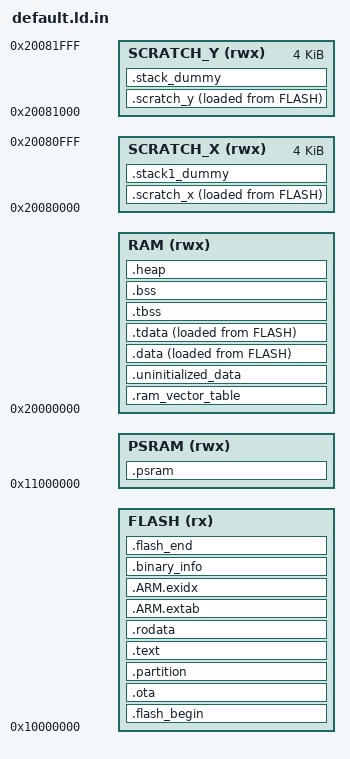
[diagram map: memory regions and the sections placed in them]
MEMORY
{
    FLASH(rx) : ORIGIN = 0x10000000, LENGTH = @FLASH_LENGTH@
    PSRAM(rwx) : ORIGIN = 0x11000000, LENGTH = @PSRAM_LENGTH@
    RAM(rwx) : ORIGIN = 0x20000000, LENGTH = @RAM_LENGTH@
    SCRATCH_X(rwx) : ORIGIN = 0x20080000, LENGTH = 4k
    SCRATCH_Y(rwx) : ORIGIN = 0x20081000, LENGTH = 4k
}

PROVIDE ( _EEPROM_start = @EEPROM_START@ );
PROVIDE ( _FS_start     = @FS_START@ );
PROVIDE ( _FS_end       = @FS_END@ );

ENTRY(_entry_point)

SECTIONS
{
    .flash_begin : {
        __flash_binary_start = .;
    } > FLASH

    .ota : {
        KEEP (*(.OTA))
        *ota.o
    } > FLASH

    .partition : {
        . = __flash_binary_start + 0x2ff0;
        LONG(@FS_START@)
        LONG(@FS_END@)
        LONG(@EEPROM_START@)
        LONG(@FLASH_LENGTH@)
    } > FLASH

    .text : {
        KEEP (*(.vectors))
        __logical_binary_start = .;
        KEEP (*(.binary_info_header))
        __binary_info_header_end = .;
        KEEP (*(.embedded_block))
        __embedded_block_end = .;
        KEEP (*(.reset))
        *(.init)
        *libgcc.a:cmse_nonsecure_call.o
        *(EXCLUDE_FILE(*libgcc.a: *libc.a:*lib_a-mem*.o *libm.a:) .text*)
        *(.fini)
        *crtbegin.o(.ctors)
        *crtbegin?.o(.ctors)
        *(EXCLUDE_FILE(*crtend?.o *crtend.o) .ctors)
        *(SORT(.ctors.*))
        *(.ctors)
        *crtbegin.o(.dtors)
        *crtbegin?.o(.dtors)
        *(EXCLUDE_FILE(*crtend?.o *crtend.o) .dtors)
        *(SORT(.dtors.*))
        *(.dtors)
        . = ALIGN(4);
        PROVIDE_HIDDEN (__preinit_array_start = .);
        KEEP(*(SORT(.preinit_array.*)))
        KEEP(*(.preinit_array))
        PROVIDE_HIDDEN (__preinit_array_end = .);
        . = ALIGN(4);
        PROVIDE_HIDDEN (__init_array_start = .);
        KEEP(*(SORT(.init_array.*)))
        KEEP(*(.init_array))
        PROVIDE_HIDDEN (__init_array_end = .);
        . = ALIGN(4);
        PROVIDE_HIDDEN (__fini_array_start = .);
        *(SORT(.fini_array.*))
        *(.fini_array)
        PROVIDE_HIDDEN (__fini_array_end = .);
        *(.eh_frame*)
        . = ALIGN(4);
    } > FLASH

    .rodata : {
        *(EXCLUDE_FILE(*libgcc.a: *libc.a:*lib_a-mem*.o *libm.a:) .rodata*)
        *(.srodata*)
        . = ALIGN(4);
        *(SORT_BY_ALIGNMENT(SORT_BY_NAME(.flashdata*)))
        . = ALIGN(4);
    } > FLASH

    .ARM.extab : {
        *(.ARM.extab* .gnu.linkonce.armextab.*)
    } > FLASH

    __exidx_start = .;
    .ARM.exidx : {
        *(.ARM.exidx* .gnu.linkonce.armexidx.*)
    } > FLASH
    __exidx_end = .;

    . = ALIGN(4);
    __binary_info_start = .;
    .binary_info : {
        KEEP(*(.binary_info.keep.*))
        *(.binary_info.*)
    } > FLASH
    __binary_info_end = .;
    . = ALIGN(4);

    .ram_vector_table (NOLOAD) : {
        *(.ram_vector_table)
    } > RAM

    .uninitialized_data (NOLOAD) : {
        . = ALIGN(4);
        *(.uninitialized_data*)
    } > RAM

    .data : {
        __data_start__ = .;
        *(vtable)
        *(.time_critical*)
        *(.text*)
        . = ALIGN(4);
        *(.rodata*)
        . = ALIGN(4);
        *(.data*)
        *(.sdata*)
        . = ALIGN(4);
        *(.after_data.*)
        . = ALIGN(4);
        PROVIDE_HIDDEN (__mutex_array_start = .);
        KEEP(*(SORT(.mutex_array.*)))
        KEEP(*(.mutex_array))
        PROVIDE_HIDDEN (__mutex_array_end = .);
        *(.jcr)
        . = ALIGN(4);
    } > RAM AT> FLASH

    .tdata : {
        . = ALIGN(4);
        *(.tdata .tdata.* .gnu.linkonce.td.*)
        __tdata_end = .;
    } > RAM AT> FLASH
    PROVIDE(__data_end__ = .);
    __etext = LOADADDR(.data);

    .tbss (NOLOAD) : {
        . = ALIGN(4);
        __bss_start__ = .;
        __tls_base = .;
        *(.tbss .tbss.* .gnu.linkonce.tb.*)
        *(.tcommon)
        __tls_end = .;
    } > RAM

    .bss (NOLOAD) : {
        . = ALIGN(4);
        __tbss_end = .;
        *(SORT_BY_ALIGNMENT(SORT_BY_NAME(.bss*)))
        *(COMMON)
        PROVIDE(__global_pointer$ = . + 2K);
        *(.sbss*)
        . = ALIGN(4);
        __bss_end__ = .;
    } > RAM

    .heap (NOLOAD) : {
        __end__ = .;
        end = __end__;
        KEEP(*(.heap*))
        . = ALIGN(4);
        __HeapLimit = .;
    } > RAM

    .scratch_x : {
        __scratch_x_start__ = .;
        *(.scratch_x.*)
        . = ALIGN(4);
        __scratch_x_end__ = .;
    } > SCRATCH_X AT > FLASH
    __scratch_x_source__ = LOADADDR(.scratch_x);

    .scratch_y : {
        __scratch_y_start__ = .;
        *(.scratch_y.*)
        . = ALIGN(4);
        __scratch_y_end__ = .;
    } > SCRATCH_Y AT > FLASH
    __scratch_y_source__ = LOADADDR(.scratch_y);

    .stack1_dummy (NOLOAD) : {
        *(.stack1*)
    } > SCRATCH_X

    .stack_dummy (NOLOAD) : {
        KEEP(*(.stack*))
    } > SCRATCH_Y

    .flash_end : {
        KEEP(*(.embedded_end_block*))
        PROVIDE(__flash_binary_end = .);
    } > FLASH = 0xaa

    .psram (NOLOAD) : {
        __psram_start__ = .;
        *(.psram*)
        . = ALIGN(4096);
        __psram_heap_start__ = .;
    } > PSRAM

    __StackLimit = ORIGIN(RAM) + LENGTH(RAM);
    __StackOneTop = ORIGIN(SCRATCH_X) + LENGTH(SCRATCH_X);
    __StackTop = ORIGIN(SCRATCH_Y) + LENGTH(SCRATCH_Y);
    __StackOneBottom = __StackOneTop - SIZEOF(.stack1_dummy);
    __StackBottom = __StackTop - SIZEOF(.stack_dummy);
    PROVIDE(__stack = __StackTop);

    PROVIDE (__heap_start = __end__);
    PROVIDE (__heap_end = __HeapLimit);
    PROVIDE( __tls_align = MAX(ALIGNOF(.tdata), ALIGNOF(.tbss)) );
    PROVIDE( __tls_size_align = (__tls_size + __tls_align - 1) & ~(__tls_align - 1));
    PROVIDE( __arm32_tls_tcb_offset = MAX(8, __tls_align) );

    PROVIDE (__psram_start = __psram_start__);
    PROVIDE (__psram_heap_start = __psram_heap_start__);

    PROVIDE (_end = __end__);
    PROVIDE (__llvm_libc_heap_limit = __HeapLimit);

    ASSERT(__StackLimit >= __HeapLimit, "region RAM overflowed")
    ASSERT( __binary_info_header_end - __logical_binary_start <= 1024, "Binary info must be in first 1024 bytes of the binary")
    ASSERT( __embedded_block_end - __logical_binary_start <= 4096, "Embedded block must be in first 4096 bytes of the binary")
}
